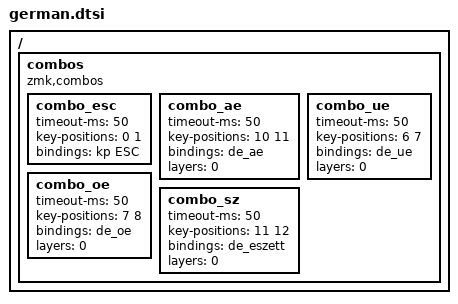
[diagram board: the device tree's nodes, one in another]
/* German umlauts */

#include "helper.h"

ZMK_UNICODE_PAIR( de_ae,   KP_N1, KP_N3, KP_N2,  KP_N1, KP_N4, KP_N2 )
ZMK_UNICODE_PAIR( de_oe,   KP_N1, KP_N4, KP_N8,  KP_N1, KP_N5, KP_N3 )
ZMK_UNICODE_PAIR( de_ue,   KP_N1, KP_N2, KP_N9,  KP_N1, KP_N5, KP_N4 )
ZMK_UNICODE_SINGLE( de_eszett,  KP_N2,  KP_N2,  KP_N5)

// euro sign
ZMK_UNICODE_SINGLE(euro_sign, KP_N0, A, C)  // € does not work with altcodes

/ {
  combos {
    compatible = "zmk,combos";
    combo_esc {
      timeout-ms = <50>;
      key-positions = <0 1>;
      bindings = <&kp ESC>;
    };
    combo_ae {
        timeout-ms = <50>;
        key-positions = <10 11>;
        bindings = <&de_ae>;
        layers = <0>;
    };
    combo_ue {
        timeout-ms = <50>;
        key-positions = <6 7>;
        bindings = <&de_ue>;
        layers = <0>;
    };
    combo_oe {
        timeout-ms = <50>;
        key-positions = <7 8>;
        bindings = <&de_oe>;
        layers = <0>;
    };
    combo_sz {
        timeout-ms = <50>;
        key-positions = <11 12>;
        bindings = <&de_eszett>;
        layers = <0>;
    };
  };
};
